VERSION ""

NS_ :

BS_:

BU_:

BO_ 3221225472 VECTOR__INDEPENDENT_SIG_MSG: 0 Vector__XXX
 SG_ Temperature : 0|16@1- (0.01,0) [-327.68|327.67] "d" Vector__XXX
 SG_ Pressure : 0|16@1- (0.01,0) [-327.68|327.67] "kPa" Vector__XXX
 SG_ Lin_AccZ : 0|16@1- (0.001,0) [-32.768|32.767] "g" Vector__XXX
 SG_ Lin_AccY : 0|16@1- (0.001,0) [-32.768|32.767] "g" Vector__XXX
 SG_ Lin_AccX : 0|16@1- (0.001,0) [-32.768|32.767] "g" Vector__XXX
 SG_ EulerZ : 0|16@1- (0.01,0) [-327.68|327.67] "d" Vector__XXX
 SG_ EulerY : 0|16@1- (0.01,0) [-327.68|327.67] "d" Vector__XXX
 SG_ EulerX : 0|16@1- (0.01,0) [-327.68|327.67] "d" Vector__XXX
 SG_ QuaternionZ : 0|16@1- (0.0001,0) [-3.2768|3.2767] "" Vector__XXX
 SG_ QuaternionY : 0|16@1- (0.0001,0) [-3.2768|3.2767] "" Vector__XXX
 SG_ QuaternionX : 0|16@1- (0.0001,0) [-3.2768|3.2767] "" Vector__XXX
 SG_ QuaternionW : 0|16@1- (0.0001,0) [-3.2768|3.2767] "" Vector__XXX
 SG_ Angular_RateZ : 0|16@1- (0.1,0) [-3276.8|3276.7] "d/s" Vector__XXX
 SG_ Angular_RateY : 0|16@1- (0.1,0) [-3276.8|3276.7] "d/s" Vector__XXX
 SG_ Angular_RateX : 0|16@1- (0.1,0) [-3276.8|3276.7] "d/s" Vector__XXX
 SG_ Mag_CalibratedZ : 0|16@1- (0.01,0) [-327.68|327.67] "uT" Vector__XXX
 SG_ Mag_CalibratedY : 0|16@1- (0.01,0) [-327.68|327.67] "uT" Vector__XXX
 SG_ Mag_CalibratedX : 0|16@1- (0.01,0) [-327.68|327.67] "uT" Vector__XXX
 SG_ Mag_RawZ : 0|16@1- (0.01,0) [-327.68|327.67] "uT" Vector__XXX
 SG_ Mag_RawY : 0|16@1- (0.01,0) [-327.68|327.67] "uT" Vector__XXX
 SG_ Mag_RawX : 0|16@1- (0.01,0) [-327.68|327.67] "uT" Vector__XXX
 SG_ GyroII_Align_CalibratedZ : 0|16@1- (0.1,0) [-3276.8|3276.7] "d/s" Vector__XXX
 SG_ GyroII_Align_CalibratedY : 0|16@1- (0.1,0) [-3276.8|3276.7] "d/s" Vector__XXX
 SG_ GyroII_Align_CalibratedX : 0|16@1- (0.1,0) [-3276.8|3276.7] "d/s" Vector__XXX
 SG_ GyroII_Bias_CalibratedZ : 0|16@1- (0.1,0) [-3276.8|3276.7] "d/s" Vector__XXX
 SG_ GyroII_Bias_CalibratedY : 0|16@1- (0.1,0) [-3276.8|3276.7] "d/s" Vector__XXX
 SG_ GyroII_Bias_CalibratedX : 0|16@1- (0.1,0) [-3276.8|3276.7] "d/s" Vector__XXX
 SG_ GyroII_RawZ : 0|16@1- (0.1,0) [-3276.8|3276.7] "d/s" Vector__XXX
 SG_ GyroII_RawY : 0|16@1- (0.1,0) [-3276.8|3276.7] "d/s" Vector__XXX
 SG_ GyroII_RawX : 0|16@1- (0.1,0) [-3276.8|3276.7] "d/s" Vector__XXX
 SG_ Acc_CalibratedZ : 0|16@1- (0.001,0) [-32.768|32.767] "g" Vector__XXX
 SG_ Acc_CalibratedY : 0|16@1- (0.001,0) [-32.768|32.767] "g" Vector__XXX
 SG_ Acc_CalibratedX : 0|16@1- (0.001,0) [-32.768|32.767] "g" Vector__XXX
 SG_ Acc_RawZ : 0|16@1- (0.001,0) [-32.768|32.767] "g" Vector__XXX
 SG_ Acc_RawY : 0|16@1- (0.001,0) [-32.768|32.767] "g" Vector__XXX
 SG_ Acc_RawX : 0|16@1- (0.001,0) [-32.768|32.767] "g" Vector__XXX

BO_ 1793 Heatbeat: 8 Vector__XXX

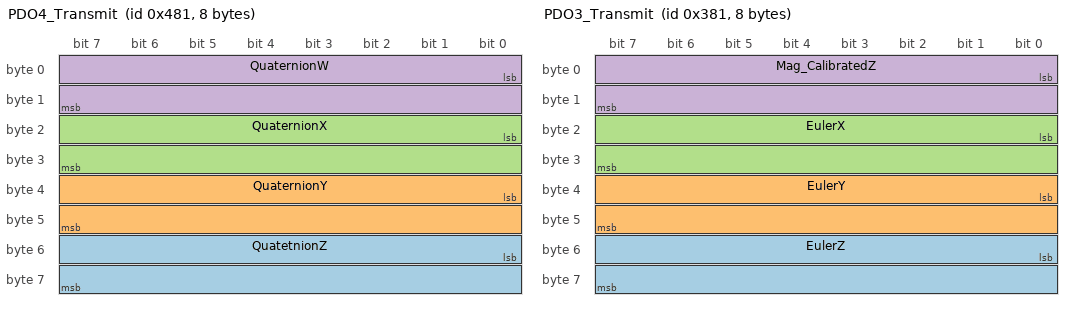
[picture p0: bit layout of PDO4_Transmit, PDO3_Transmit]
BO_ 1153 PDO4_Transmit: 8 Vector__XXX
 SG_ QuatetnionZ : 48|16@1- (0.0001,0) [-3.2768|3.2767] "" Vector__XXX
 SG_ QuaternionY : 32|16@1- (0.0001,0) [-3.2768|3.2767] "" Vector__XXX
 SG_ QuaternionX : 16|16@1- (0.0001,0) [-3.2768|3.2767] "" Vector__XXX
 SG_ QuaternionW : 0|16@1- (0.0001,0) [-3.2768|3.2767] "" Vector__XXX

BO_ 897 PDO3_Transmit: 8 Vector__XXX
 SG_ EulerZ : 48|16@1- (0.01,0) [-327.68|327.67] "d" Vector__XXX
 SG_ EulerY : 32|16@1- (0.01,0) [-327.68|327.67] "d" Vector__XXX
 SG_ EulerX : 16|16@1- (0.01,0) [-327.68|327.67] "d" Vector__XXX
 SG_ Mag_CalibratedZ : 0|16@1- (0.01,0) [-327.68|327.67] "uT" Vector__XXX

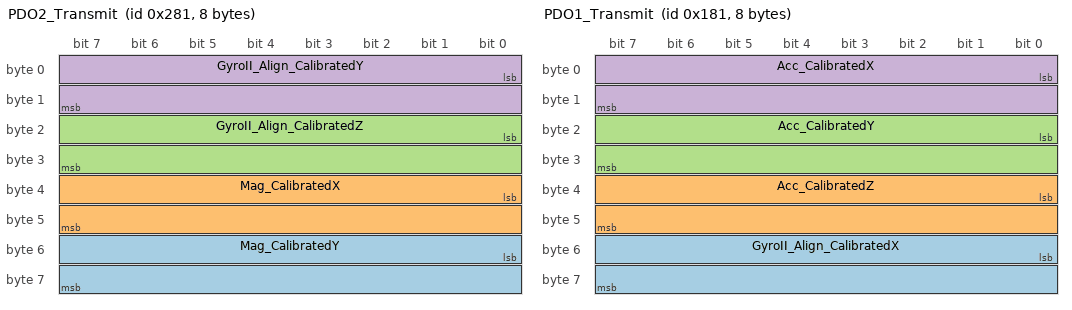
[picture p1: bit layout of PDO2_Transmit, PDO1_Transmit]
BO_ 641 PDO2_Transmit: 8 Vector__XXX
 SG_ Mag_CalibratedY : 48|16@1- (0.01,0) [-327.68|327.67] "uT" Vector__XXX
 SG_ Mag_CalibratedX : 32|16@1- (0.01,0) [-327.68|327.67] "uT" Vector__XXX
 SG_ GyroII_Align_CalibratedZ : 16|16@1- (0.1,0) [-3276.8|3276.7] "d/s" Vector__XXX
 SG_ GyroII_Align_CalibratedY : 0|16@1- (0.1,0) [-3276.8|3276.7] "d/s" Vector__XXX

BO_ 385 PDO1_Transmit: 8 Vector__XXX
 SG_ GyroII_Align_CalibratedX : 48|16@1- (0.1,0) [-3276.8|3276.7] "d/s" Vector__XXX
 SG_ Acc_CalibratedZ : 32|16@1- (0.001,0) [-32.768|32.767] "g" Vector__XXX
 SG_ Acc_CalibratedY : 16|16@1- (0.001,0) [-32.768|32.767] "g" Vector__XXX
 SG_ Acc_CalibratedX : 0|16@1- (0.001,0) [-32.768|32.767] "g" Vector__XXX

CM_ BO_ 3221225472 "This is a message for not used signals, created by Vector CANdb++ DBC OLE DB Provider.";
BA_DEF_  "BusType" STRING ;
BA_DEF_DEF_  "BusType" "CAN";
